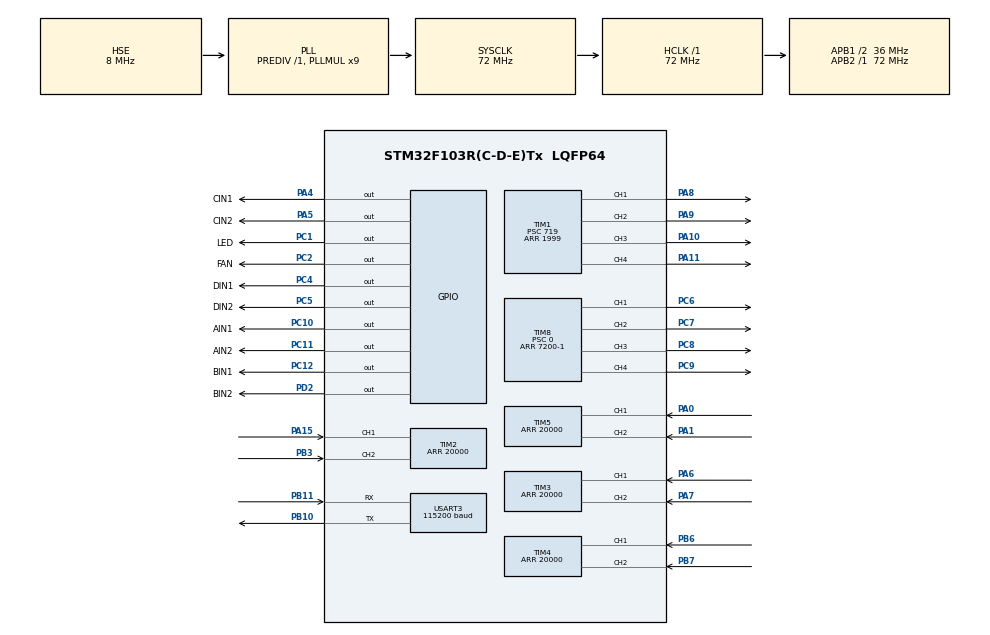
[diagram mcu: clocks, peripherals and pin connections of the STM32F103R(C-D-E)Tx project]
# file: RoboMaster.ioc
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Dma.Request0=USART3_RX
Dma.Request1=USART3_TX
Dma.USART3_RX.0.Direction=DMA_PERIPH_TO_MEMORY
Dma.USART3_RX.0.Instance=DMA1_Channel3
Dma.USART3_RX.0.MemDataAlignment=DMA_MDATAALIGN_BYTE
Dma.USART3_RX.0.MemInc=DMA_MINC_ENABLE
Dma.USART3_RX.0.Mode=DMA_NORMAL
Dma.USART3_RX.0.PeriphDataAlignment=DMA_PDATAALIGN_BYTE
Dma.USART3_RX.0.PeriphInc=DMA_PINC_DISABLE
Dma.USART3_RX.0.Priority=DMA_PRIORITY_LOW
Dma.USART3_TX.1.Direction=DMA_MEMORY_TO_PERIPH
Dma.USART3_TX.1.Instance=DMA1_Channel2
Dma.USART3_TX.1.MemDataAlignment=DMA_MDATAALIGN_BYTE
Dma.USART3_TX.1.MemInc=DMA_MINC_ENABLE
Dma.USART3_TX.1.Mode=DMA_NORMAL
Dma.USART3_TX.1.PeriphDataAlignment=DMA_PDATAALIGN_BYTE
Dma.USART3_TX.1.PeriphInc=DMA_PINC_DISABLE
Dma.USART3_TX.1.Priority=DMA_PRIORITY_LOW
FREERTOS.INCLUDE_vTaskDelayUntil=1
FREERTOS.Tasks01=defaultTask,-3,64,StartDefaultTask,Default,NULL,Dynamic,NULL,NULL;motorTask,0,128,StartmotorTask,As weak,NULL,Dynamic,NULL,NULL;SevorTask,0,128,StartSevorTask,As weak,NULL,Dynamic,NULL,NULL
FREERTOS.configMINIMAL_STACK_SIZE=64
Mcu.Family=STM32F1
Mcu.Name=STM32F103R(C-D-E)Tx
Mcu.Package=LQFP64
NVIC.DMA1_Channel2_IRQn=true\:5\:0\:false\:false\:true\:true\:false\:true\:true
NVIC.DMA1_Channel3_IRQn=true\:5\:0\:false\:false\:true\:true\:false\:true\:true
NVIC.PriorityGroup=NVIC_PRIORITYGROUP_4
NVIC.TIM6_IRQn=true\:6\:0\:true\:false\:true\:true\:true\:true\:true
NVIC.TIM7_IRQn=true\:15\:0\:false\:false\:true\:false\:false\:true\:true
NVIC.TimeBase=TIM7_IRQn
NVIC.TimeBaseIP=TIM7
NVIC.USART3_IRQn=true\:5\:0\:false\:false\:true\:true\:true\:true\:true
PA0-WKUP.Signal=S_TIM5_CH1
PA1.Signal=S_TIM5_CH2
PA10.Signal=S_TIM1_CH3
PA11.Signal=S_TIM1_CH4
PA13.Mode=Serial_Wire
PA13.Signal=SYS_JTMS-SWDIO
PA14.Mode=Serial_Wire
PA14.Signal=SYS_JTCK-SWCLK
PA15.Signal=S_TIM2_CH1_ETR
PA4.GPIO_Label=CIN1
PA4.Signal=GPIO_Output
PA5.GPIO_Label=CIN2
PA5.Signal=GPIO_Output
PA6.Signal=S_TIM3_CH1
PA7.Signal=S_TIM3_CH2
PA8.Signal=S_TIM1_CH1
PA9.Signal=S_TIM1_CH2
PB10.Mode=Asynchronous
PB10.Signal=USART3_TX
PB11.Mode=Asynchronous
PB11.Signal=USART3_RX
PB3.Signal=S_TIM2_CH2
PB6.Signal=S_TIM4_CH1
PB7.Signal=S_TIM4_CH2
PC1.GPIO_Label=LED
PC1.Signal=GPIO_Output
PC10.GPIO_Label=AIN1
PC10.Signal=GPIO_Output
PC11.GPIO_Label=AIN2
PC11.Signal=GPIO_Output
PC12.GPIO_Label=BIN1
PC12.Signal=GPIO_Output
PC2.GPIO_Label=FAN
PC2.Signal=GPIO_Output
PC4.GPIO_Label=DIN1
PC4.Signal=GPIO_Output
PC5.GPIO_Label=DIN2
PC5.Signal=GPIO_Output
PC6.Signal=S_TIM8_CH1
PC7.Signal=S_TIM8_CH2
PC8.Signal=S_TIM8_CH3
PC9.Signal=S_TIM8_CH4
PD0-OSC_IN.Mode=HSE-External-Oscillator
PD0-OSC_IN.Signal=RCC_OSC_IN
PD1-OSC_OUT.Mode=HSE-External-Oscillator
PD1-OSC_OUT.Signal=RCC_OSC_OUT
PD2.GPIO_Label=BIN2
PD2.Signal=GPIO_Output
ProjectManager.HeapSize=0x200
ProjectManager.StackSize=0x400
ProjectManager.TargetToolchain=MDK-ARM V5.32
RCC.AHBFreq_Value=72000000
RCC.APB1CLKDivider=RCC_HCLK_DIV2
RCC.APB1Freq_Value=36000000
RCC.APB1TimFreq_Value=72000000
RCC.APB2Freq_Value=72000000
RCC.APB2TimFreq_Value=72000000
RCC.HCLKFreq_Value=72000000
RCC.PLLMUL=RCC_PLL_MUL9
RCC.PLLSourceVirtual=RCC_PLLSOURCE_HSE
RCC.SYSCLKFreq_VALUE=72000000
RCC.SYSCLKSource=RCC_SYSCLKSOURCE_PLLCLK
RCC.USBFreq_Value=72000000
SH.S_TIM1_CH1.0=TIM1_CH1,PWM Generation1 CH1
SH.S_TIM1_CH2.0=TIM1_CH2,PWM Generation2 CH2
SH.S_TIM1_CH3.0=TIM1_CH3,PWM Generation3 CH3
SH.S_TIM1_CH4.0=TIM1_CH4,PWM Generation4 CH4
SH.S_TIM2_CH1_ETR.0=TIM2_CH1,Encoder_Interface
SH.S_TIM2_CH2.0=TIM2_CH2,Encoder_Interface
SH.S_TIM3_CH1.0=TIM3_CH1,Encoder_Interface
SH.S_TIM3_CH2.0=TIM3_CH2,Encoder_Interface
SH.S_TIM4_CH1.0=TIM4_CH1,Encoder_Interface
SH.S_TIM4_CH2.0=TIM4_CH2,Encoder_Interface
SH.S_TIM5_CH1.0=TIM5_CH1,Encoder_Interface
SH.S_TIM5_CH2.0=TIM5_CH2,Encoder_Interface
SH.S_TIM8_CH1.0=TIM8_CH1,PWM Generation1 CH1
SH.S_TIM8_CH2.0=TIM8_CH2,PWM Generation2 CH2
SH.S_TIM8_CH3.0=TIM8_CH3,PWM Generation3 CH3
SH.S_TIM8_CH4.0=TIM8_CH4,PWM Generation4 CH4
TIM1.AutoReloadPreload=TIM_AUTORELOAD_PRELOAD_ENABLE
TIM1.Channel-PWM\ Generation1\ CH1=TIM_CHANNEL_1
TIM1.Channel-PWM\ Generation2\ CH2=TIM_CHANNEL_2
TIM1.Channel-PWM\ Generation3\ CH3=TIM_CHANNEL_3
TIM1.Channel-PWM\ Generation4\ CH4=TIM_CHANNEL_4
TIM1.Period=1999
TIM1.Prescaler=719
TIM1.Pulse-PWM\ Generation1\ CH1=0
TIM2.EncoderMode=TIM_ENCODERMODE_TI12
TIM2.Period=20000
TIM3.EncoderMode=TIM_ENCODERMODE_TI12
TIM3.Period=20000
TIM4.EncoderMode=TIM_ENCODERMODE_TI12
TIM4.Period=20000
TIM5.EncoderMode=TIM_ENCODERMODE_TI12
TIM5.Period=20000
TIM6.Period=10000-1
TIM6.Prescaler=72-1
TIM8.Channel-PWM\ Generation1\ CH1=TIM_CHANNEL_1
TIM8.Channel-PWM\ Generation2\ CH2=TIM_CHANNEL_2
TIM8.Channel-PWM\ Generation3\ CH3=TIM_CHANNEL_3
TIM8.Channel-PWM\ Generation4\ CH4=TIM_CHANNEL_4
TIM8.Period=7200-1
TIM8.Prescaler=0
USART3.BaudRate=115200
USART3.Mode=MODE_TX_RX
USART3.VirtualMode=VM_ASYNC
VP_FREERTOS_VS_CMSIS_V1.Mode=CMSIS_V1
VP_SYS_VS_tim7.Mode=TIM7
VP_TIM6_VS_ClockSourceINT.Mode=Enable_Timer
VP_TIM8_VS_ClockSourceINT.Mode=Internal
board=custom

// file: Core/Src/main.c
/* USER CODE BEGIN Header */
/**
  ******************************************************************************
  * @file           : main.c
  * @brief          : Main program body
  ******************************************************************************
  * @attention
  *
  * Copyright (c) 2024 STMicroelectronics.
  * All rights reserved.
  *
  * This software is licensed under terms that can be found in the LICENSE file
  * in the root directory of this software component.
  * If no LICENSE file comes with this software, it is provided AS-IS.
  *
  ******************************************************************************
  */
/* USER CODE END Header */
#include "main.h"
#include "cmsis_os.h"
#include "dma.h"
#include "tim.h"
#include "usart.h"
#include "gpio.h"

/* USER CODE BEGIN PD */
uint8_t data[11];
/* USER CODE END PD */

void SystemClock_Config(void);
void MX_FREERTOS_Init(void);

/* USER CODE BEGIN 0 */
   void HAL_UART_RxCpltCallback(UART_HandleTypeDef *huart)
{
	if(huart->Instance== USART3)
	{
    uart_to_remote(data);
	}
	HAL_UART_Receive_DMA(&huart3,data,11);
}

/* USER CODE END 0 */

int main(void)
{

  /* MCU Configuration--------------------------------------------------------*/

  /* Reset of all peripherals, Initializes the Flash interface and the Systick. */
  HAL_Init();

  /* Configure the system clock */
  SystemClock_Config();

  /* Initialize all configured peripherals */
  MX_GPIO_Init();
  MX_DMA_Init();
  MX_TIM6_Init();
  MX_TIM8_Init();
  MX_TIM2_Init();
  MX_TIM3_Init();
  MX_TIM4_Init();
  MX_TIM5_Init();
  MX_USART3_UART_Init();
  MX_TIM1_Init();
  /* USER CODE BEGIN 2 */
  HAL_UART_Receive_DMA(&huart3,data,11);

  //HAL_TIM_Base_Start(&htim2);
  //HAL_TIM_MspPostInit(&htim2);

  /* USER CODE END 2 */

  /* Call init function for freertos objects (in freertos.c) */
  MX_FREERTOS_Init();

  /* Start scheduler */
  osKernelStart();

  /* We should never get here as control is now taken by the scheduler */
  /* Infinite loop */
  /* USER CODE BEGIN WHILE */
  while (1)
  {
		HAL_Delay(1000);

		/*__HAL_TIM_SetCompare(&htim1, TIM_CHANNEL_2, 180/ 180 * 2000 + 500);
		HAL_Delay(10000);*/

    //HAL_UART_Transmit_DMA(&huart2,(uint8_t*)"Hello world\r\n",sizeof("Hello world\r\n"));
    /* USER CODE END WHILE */

  }
}

void SystemClock_Config(void)
{
  RCC_OscInitTypeDef RCC_OscInitStruct = {0};
  RCC_ClkInitTypeDef RCC_ClkInitStruct = {0};

  /** Initializes the RCC Oscillators according to the specified parameters
  * in the RCC_OscInitTypeDef structure.
  */
  RCC_OscInitStruct.OscillatorType = RCC_OSCILLATORTYPE_HSE;
  RCC_OscInitStruct.HSEState = RCC_HSE_ON;
  RCC_OscInitStruct.HSEPredivValue = RCC_HSE_PREDIV_DIV1;
  RCC_OscInitStruct.HSIState = RCC_HSI_ON;
  RCC_OscInitStruct.PLL.PLLState = RCC_PLL_ON;
  RCC_OscInitStruct.PLL.PLLSource = RCC_PLLSOURCE_HSE;
  RCC_OscInitStruct.PLL.PLLMUL = RCC_PLL_MUL9;
  if (HAL_RCC_OscConfig(&RCC_OscInitStruct) != HAL_OK)
  {
    Error_Handler();
  }

  /** Initializes the CPU, AHB and APB buses clocks
  */
  RCC_ClkInitStruct.ClockType = RCC_CLOCKTYPE_HCLK|RCC_CLOCKTYPE_SYSCLK
                              |RCC_CLOCKTYPE_PCLK1|RCC_CLOCKTYPE_PCLK2;
  RCC_ClkInitStruct.SYSCLKSource = RCC_SYSCLKSOURCE_PLLCLK;
  RCC_ClkInitStruct.AHBCLKDivider = RCC_SYSCLK_DIV1;
  RCC_ClkInitStruct.APB1CLKDivider = RCC_HCLK_DIV2;
  RCC_ClkInitStruct.APB2CLKDivider = RCC_HCLK_DIV1;

  if (HAL_RCC_ClockConfig(&RCC_ClkInitStruct, FLASH_LATENCY_2) != HAL_OK)
  {
    Error_Handler();
  }
}

void HAL_TIM_PeriodElapsedCallback(TIM_HandleTypeDef *htim)
{
  if (htim->Instance == TIM7) {
    HAL_IncTick();
  }
}

void Error_Handler(void)
{
  __disable_irq();
  while (1)
  {
  }
}

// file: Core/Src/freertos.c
/* USER CODE BEGIN Header */
/**
  ******************************************************************************
  * File Name          : freertos.c
  * Description        : Code for freertos applications
  ******************************************************************************
  * @attention
  *
  * Copyright (c) 2024 STMicroelectronics.
  * All rights reserved.
  *
  * This software is licensed under terms that can be found in the LICENSE file
  * in the root directory of this software component.
  * If no LICENSE file comes with this software, it is provided AS-IS.
  *
  ******************************************************************************
  */
/* USER CODE END Header */

#include "FreeRTOS.h"
#include "task.h"
#include "main.h"
#include "cmsis_os.h"

osThreadId defaultTaskHandle;
osThreadId motorTaskHandle;
osThreadId SevorTaskHandle;

void StartDefaultTask(void const * argument);
void StartmotorTask(void const * argument);
void StartSevorTask(void const * argument);

void MX_FREERTOS_Init(void); /* (MISRA C 2004 rule 8.1) */

/* GetIdleTaskMemory prototype (linked to static allocation support) */
void vApplicationGetIdleTaskMemory( StaticTask_t **ppxIdleTaskTCBBuffer, StackType_t **ppxIdleTaskStackBuffer, uint32_t *pulIdleTaskStackSize );

/* USER CODE BEGIN GET_IDLE_TASK_MEMORY */
static StaticTask_t xIdleTaskTCBBuffer;
static StackType_t xIdleStack[configMINIMAL_STACK_SIZE];

void vApplicationGetIdleTaskMemory( StaticTask_t **ppxIdleTaskTCBBuffer, StackType_t **ppxIdleTaskStackBuffer, uint32_t *pulIdleTaskStackSize )
{
  *ppxIdleTaskTCBBuffer = &xIdleTaskTCBBuffer;
  *ppxIdleTaskStackBuffer = &xIdleStack[0];
  *pulIdleTaskStackSize = configMINIMAL_STACK_SIZE;
  /* place for user code */
}
/* USER CODE END GET_IDLE_TASK_MEMORY */

void MX_FREERTOS_Init(void) {

  /* Create the thread(s) */
  /* definition and creation of defaultTask */
  osThreadDef(defaultTask, StartDefaultTask, osPriorityIdle, 0, 64);
  defaultTaskHandle = osThreadCreate(osThread(defaultTask), NULL);

  /* definition and creation of motorTask */
  osThreadDef(motorTask, StartmotorTask, osPriorityNormal, 0, 128);
  motorTaskHandle = osThreadCreate(osThread(motorTask), NULL);

  /* definition and creation of SevorTask */
  osThreadDef(SevorTask, StartSevorTask, osPriorityNormal, 0, 128);
  SevorTaskHandle = osThreadCreate(osThread(SevorTask), NULL);

}

void StartDefaultTask(void const * argument)
{
  for(;;)
  {
    osDelay(1);
  }
}

__weak void StartmotorTask(void const * argument)
{
  for(;;)
  {
    osDelay(1);
  }
}

__weak void StartSevorTask(void const * argument)
{
  for(;;)
  {
    osDelay(1);
  }
}
